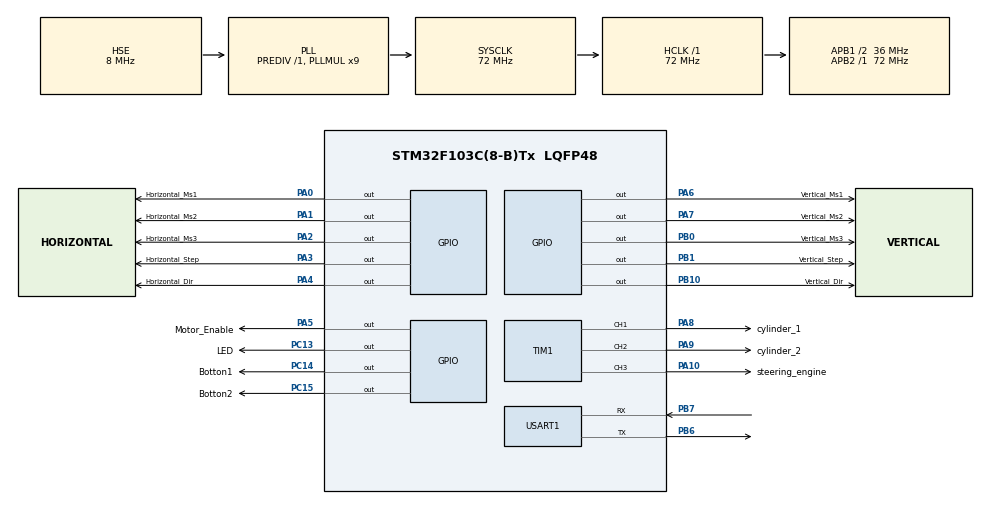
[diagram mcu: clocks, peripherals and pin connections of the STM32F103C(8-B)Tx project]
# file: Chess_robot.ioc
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Dma.Request0=USART1_RX
Dma.USART1_RX.0.Direction=DMA_PERIPH_TO_MEMORY
Dma.USART1_RX.0.Instance=DMA1_Channel5
Dma.USART1_RX.0.MemDataAlignment=DMA_MDATAALIGN_BYTE
Dma.USART1_RX.0.MemInc=DMA_MINC_ENABLE
Dma.USART1_RX.0.Mode=DMA_NORMAL
Dma.USART1_RX.0.PeriphDataAlignment=DMA_PDATAALIGN_BYTE
Dma.USART1_RX.0.PeriphInc=DMA_PINC_DISABLE
Dma.USART1_RX.0.Priority=DMA_PRIORITY_LOW
Mcu.Family=STM32F1
Mcu.Name=STM32F103C(8-B)Tx
Mcu.Package=LQFP48
NVIC.DMA1_Channel5_IRQn=true\:0\:0\:false\:false\:true\:false\:true\:true
NVIC.PriorityGroup=NVIC_PRIORITYGROUP_4
NVIC.USART1_IRQn=true\:0\:0\:false\:false\:true\:true\:true\:true
PA0-WKUP.GPIO_Label=Horizontal_Ms1
PA0-WKUP.Signal=GPIO_Output
PA1.GPIO_Label=Horizontal_Ms2
PA1.Signal=GPIO_Output
PA10.GPIO_Label=steering_engine
PA10.Signal=S_TIM1_CH3
PA13.Mode=Serial_Wire
PA13.Signal=SYS_JTMS-SWDIO
PA14.Mode=Serial_Wire
PA14.Signal=SYS_JTCK-SWCLK
PA2.GPIO_Label=Horizontal_Ms3
PA2.Signal=GPIO_Output
PA3.GPIO_Label=Horizontal_Step
PA3.Signal=GPIO_Output
PA4.GPIO_Label=Horizontal_Dir
PA4.Signal=GPIO_Output
PA5.GPIO_Label=Motor_Enable
PA5.Signal=GPIO_Output
PA6.GPIO_Label=Vertical_Ms1
PA6.Signal=GPIO_Output
PA7.GPIO_Label=Vertical_Ms2
PA7.Signal=GPIO_Output
PA8.GPIO_Label=cylinder_1
PA8.Signal=S_TIM1_CH1
PA9.GPIO_Label=cylinder_2
PA9.Signal=S_TIM1_CH2
PB0.GPIO_Label=Vertical_Ms3
PB0.Signal=GPIO_Output
PB1.GPIO_Label=Vertical_Step
PB1.Signal=GPIO_Output
PB10.GPIO_Label=Vertical_Dir
PB10.Signal=GPIO_Output
PB6.Mode=Asynchronous
PB6.Signal=USART1_TX
PB7.Mode=Asynchronous
PB7.Signal=USART1_RX
PC13-TAMPER-RTC.GPIO_Label=LED
PC13-TAMPER-RTC.Signal=GPIO_Output
PC14-OSC32_IN.GPIO_Label=Botton1
PC14-OSC32_IN.Signal=GPIO_Output
PC15-OSC32_OUT.GPIO_Label=Botton2
PC15-OSC32_OUT.Signal=GPIO_Output
PD0-OSC_IN.Mode=HSE-External-Oscillator
PD0-OSC_IN.Signal=RCC_OSC_IN
PD1-OSC_OUT.Mode=HSE-External-Oscillator
PD1-OSC_OUT.Signal=RCC_OSC_OUT
ProjectManager.HeapSize=0x200
ProjectManager.StackSize=0x400
ProjectManager.TargetToolchain=Makefile
RCC.AHBFreq_Value=72000000
RCC.APB1CLKDivider=RCC_HCLK_DIV2
RCC.APB1Freq_Value=36000000
RCC.APB1TimFreq_Value=72000000
RCC.APB2Freq_Value=72000000
RCC.APB2TimFreq_Value=72000000
RCC.HCLKFreq_Value=72000000
RCC.PLLMUL=RCC_PLL_MUL9
RCC.PLLSourceVirtual=RCC_PLLSOURCE_HSE
RCC.SYSCLKFreq_VALUE=72000000
RCC.SYSCLKSource=RCC_SYSCLKSOURCE_PLLCLK
RCC.USBFreq_Value=72000000
SH.S_TIM1_CH1.0=TIM1_CH1,PWM Generation1 CH1
SH.S_TIM1_CH2.0=TIM1_CH2,PWM Generation2 CH2
SH.S_TIM1_CH3.0=TIM1_CH3,PWM Generation3 CH3
TIM1.Channel-PWM\ Generation1\ CH1=TIM_CHANNEL_1
TIM1.Channel-PWM\ Generation2\ CH2=TIM_CHANNEL_2
TIM1.Channel-PWM\ Generation3\ CH3=TIM_CHANNEL_3
USART1.VirtualMode=VM_ASYNC
board=custom

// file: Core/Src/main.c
/* USER CODE BEGIN Header */
/**
  ******************************************************************************
  * @file           : main.c
  * @brief          : Main program body
  ******************************************************************************
  * @attention
  *
  * Copyright (c) 2025 STMicroelectronics.
  * All rights reserved.
  *
  * This software is licensed under terms that can be found in the LICENSE file
  * in the root directory of this software component.
  * If no LICENSE file comes with this software, it is provided AS-IS.
  *
  ******************************************************************************
  */
/* USER CODE END Header */
#include "main.h"
#include "dma.h"
#include "tim.h"
#include "usart.h"
#include "gpio.h"

void SystemClock_Config(void);

int main(void)
{

  /* MCU Configuration--------------------------------------------------------*/

  /* Reset of all peripherals, Initializes the Flash interface and the Systick. */
  HAL_Init();

  /* Configure the system clock */
  SystemClock_Config();

  /* Initialize all configured peripherals */
  MX_GPIO_Init();
  MX_DMA_Init();
  MX_USART1_UART_Init();
  MX_TIM1_Init();
  /* USER CODE BEGIN 2 */
  //使能电机
    HAL_GPIO_WritePin(Motor_Enable_GPIO_Port,Motor_Enable_Pin,GPIO_PIN_RESET);
    //确定电机旋转方向
    HAL_GPIO_WritePin(Horizontal_Dir_GPIO_Port,Horizontal_Dir_Pin,GPIO_PIN_RESET);

      //全步进模式
    HAL_GPIO_WritePin(Horizontal_Ms1_GPIO_Port,Horizontal_Ms1_Pin,GPIO_PIN_RESET);
    HAL_GPIO_WritePin(Horizontal_Ms2_GPIO_Port,Horizontal_Ms2_Pin,GPIO_PIN_RESET);
    HAL_GPIO_WritePin(Horizontal_Ms3_GPIO_Port,Horizontal_Ms3_Pin,GPIO_PIN_RESET);

  /* USER CODE END 2 */

  /* Infinite loop */
  /* USER CODE BEGIN WHILE */

  while (1)
  {
    for (int  i = 0; i < 200; i++)
    {
      HAL_GPIO_TogglePin(Horizontal_Step_GPIO_Port,Horizontal_Step_Pin);
      HAL_Delay(1);
    }
    HAL_Delay(2000);
    /* USER CODE END WHILE */

  }
}

void SystemClock_Config(void)
{
  RCC_OscInitTypeDef RCC_OscInitStruct = {0};
  RCC_ClkInitTypeDef RCC_ClkInitStruct = {0};

  /** Initializes the RCC Oscillators according to the specified parameters
  * in the RCC_OscInitTypeDef structure.
  */
  RCC_OscInitStruct.OscillatorType = RCC_OSCILLATORTYPE_HSE;
  RCC_OscInitStruct.HSEState = RCC_HSE_ON;
  RCC_OscInitStruct.HSEPredivValue = RCC_HSE_PREDIV_DIV1;
  RCC_OscInitStruct.HSIState = RCC_HSI_ON;
  RCC_OscInitStruct.PLL.PLLState = RCC_PLL_ON;
  RCC_OscInitStruct.PLL.PLLSource = RCC_PLLSOURCE_HSE;
  RCC_OscInitStruct.PLL.PLLMUL = RCC_PLL_MUL9;
  if (HAL_RCC_OscConfig(&RCC_OscInitStruct) != HAL_OK)
  {
    Error_Handler();
  }

  /** Initializes the CPU, AHB and APB buses clocks
  */
  RCC_ClkInitStruct.ClockType = RCC_CLOCKTYPE_HCLK|RCC_CLOCKTYPE_SYSCLK
                              |RCC_CLOCKTYPE_PCLK1|RCC_CLOCKTYPE_PCLK2;
  RCC_ClkInitStruct.SYSCLKSource = RCC_SYSCLKSOURCE_PLLCLK;
  RCC_ClkInitStruct.AHBCLKDivider = RCC_SYSCLK_DIV1;
  RCC_ClkInitStruct.APB1CLKDivider = RCC_HCLK_DIV2;
  RCC_ClkInitStruct.APB2CLKDivider = RCC_HCLK_DIV1;

  if (HAL_RCC_ClockConfig(&RCC_ClkInitStruct, FLASH_LATENCY_2) != HAL_OK)
  {
    Error_Handler();
  }
}

void Error_Handler(void)
{
  __disable_irq();
  while (1)
  {
  }
}
